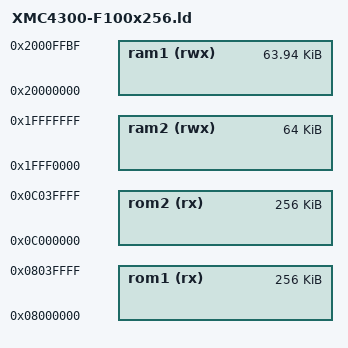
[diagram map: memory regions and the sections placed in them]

MEMORY
{
  rom1 (rx) : ORIGIN = 0x08000000, LENGTH = 0x40000
  rom2 (rx) : ORIGIN = 0x0C000000, LENGTH = 0x40000
  ram1 (rwx) : ORIGIN = 0x20000000, LENGTH = 0x0FFC0
  ram2 (rwx) : ORIGIN = 0x1FFF0000, LENGTH = 0x10000
}

